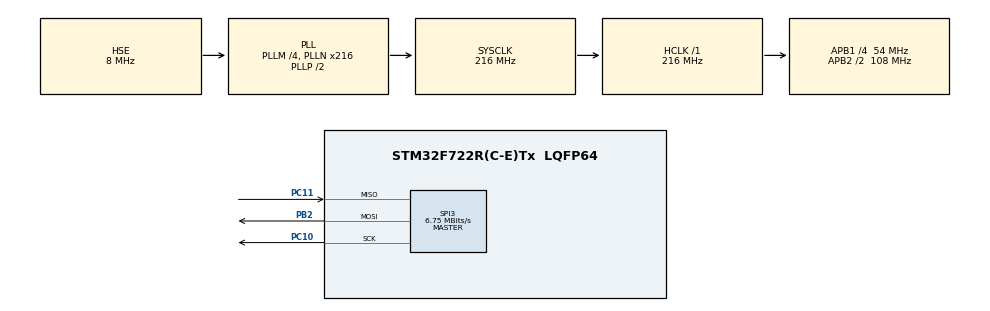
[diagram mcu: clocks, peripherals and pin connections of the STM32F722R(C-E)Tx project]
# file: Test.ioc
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CORTEX_M7.ART_ACCELERATOR_ENABLE=1
CORTEX_M7.CPU_DCache=Enabled
CORTEX_M7.CPU_ICache=Enabled
CORTEX_M7.PREFETCH_ENABLE=1
Mcu.Family=STM32F7
Mcu.Name=STM32F722R(C-E)Tx
Mcu.Package=LQFP64
NVIC.PriorityGroup=NVIC_PRIORITYGROUP_4
NVIC.SPI3_IRQn=true\:0\:0\:false\:false\:true\:true\:true\:true
PB2.Mode=Full_Duplex_Master
PB2.Signal=SPI3_MOSI
PC10.Mode=Full_Duplex_Master
PC10.Signal=SPI3_SCK
PC11.Mode=Full_Duplex_Master
PC11.Signal=SPI3_MISO
PH0-OSC_IN.Mode=HSE-External-Oscillator
PH0-OSC_IN.Signal=RCC_OSC_IN
PH1-OSC_OUT.Mode=HSE-External-Oscillator
PH1-OSC_OUT.Signal=RCC_OSC_OUT
ProjectManager.HeapSize=0x200
ProjectManager.StackSize=0x400
ProjectManager.TargetToolchain=STM32CubeIDE
RCC.AHBFreq_Value=216000000
RCC.APB1CLKDivider=RCC_HCLK_DIV4
RCC.APB1Freq_Value=54000000
RCC.APB1TimFreq_Value=108000000
RCC.APB2CLKDivider=RCC_HCLK_DIV2
RCC.APB2Freq_Value=108000000
RCC.APB2TimFreq_Value=216000000
RCC.CortexFreq_Value=216000000
RCC.HCLKFreq_Value=216000000
RCC.HSE_VALUE=8000000
RCC.HSI_VALUE=16000000
RCC.LSE_VALUE=32768
RCC.PLLM=4
RCC.PLLN=216
RCC.PLLSourceVirtual=RCC_PLLSOURCE_HSE
RCC.SYSCLKFreq_VALUE=216000000
RCC.SYSCLKSource=RCC_SYSCLKSOURCE_PLLCLK
RCC.USBFreq_Value=216000000
RCC.VCOOutputFreq_Value=432000000
SPI3.BaudRatePrescaler=SPI_BAUDRATEPRESCALER_8
SPI3.CalculateBaudRate=6.75 MBits/s
SPI3.DataSize=SPI_DATASIZE_8BIT
SPI3.Direction=SPI_DIRECTION_2LINES
SPI3.Mode=SPI_MODE_MASTER
SPI3.NSSPMode=SPI_NSS_PULSE_DISABLE
SPI3.VirtualType=VM_MASTER
board=custom

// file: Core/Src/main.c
/* USER CODE BEGIN Header */
/**
  ******************************************************************************
  * @file           : main.c
  * @brief          : Main program body
  ******************************************************************************
  * @attention
  *
  * Copyright (c) 2022 STMicroelectronics.
  * All rights reserved.
  *
  * This software is licensed under terms that can be found in the LICENSE file
  * in the root directory of this software component.
  * If no LICENSE file comes with this software, it is provided AS-IS.
  *
  ******************************************************************************
  */
/* USER CODE END Header */
#include "main.h"

SPI_HandleTypeDef hspi3;

void SystemClock_Config(void);
static void MX_GPIO_Init(void);
static void MX_SPI3_Init(void);

int main(void)
{

  /* Enable I-Cache---------------------------------------------------------*/
  SCB_EnableICache();

  /* Enable D-Cache---------------------------------------------------------*/
  SCB_EnableDCache();

  /* MCU Configuration--------------------------------------------------------*/

  /* Reset of all peripherals, Initializes the Flash interface and the Systick. */
  HAL_Init();

  /* Configure the system clock */
  SystemClock_Config();

  /* Initialize all configured peripherals */
  MX_GPIO_Init();
  MX_SPI3_Init();
  /* USER CODE BEGIN 2 */
  SystemCoreClockUpdate();
  /* USER CODE END 2 */

  /* Infinite loop */
  while (1)
  {

  }
}

void SystemClock_Config(void)
{
  RCC_OscInitTypeDef RCC_OscInitStruct = {0};
  RCC_ClkInitTypeDef RCC_ClkInitStruct = {0};

  /** Configure the main internal regulator output voltage
  */
  __HAL_RCC_PWR_CLK_ENABLE();
  __HAL_PWR_VOLTAGESCALING_CONFIG(PWR_REGULATOR_VOLTAGE_SCALE1);

  /** Initializes the RCC Oscillators according to the specified parameters
  * in the RCC_OscInitTypeDef structure.
  */
  RCC_OscInitStruct.OscillatorType = RCC_OSCILLATORTYPE_HSE;
  RCC_OscInitStruct.HSEState = RCC_HSE_ON;
  RCC_OscInitStruct.PLL.PLLState = RCC_PLL_ON;
  RCC_OscInitStruct.PLL.PLLSource = RCC_PLLSOURCE_HSE;
  RCC_OscInitStruct.PLL.PLLM = 4;
  RCC_OscInitStruct.PLL.PLLN = 216;
  RCC_OscInitStruct.PLL.PLLP = RCC_PLLP_DIV2;
  RCC_OscInitStruct.PLL.PLLQ = 2;
  if (HAL_RCC_OscConfig(&RCC_OscInitStruct) != HAL_OK)
  {
    Error_Handler();
  }

  /** Activate the Over-Drive mode
  */
  if (HAL_PWREx_EnableOverDrive() != HAL_OK)
  {
    Error_Handler();
  }

  /** Initializes the CPU, AHB and APB buses clocks
  */
  RCC_ClkInitStruct.ClockType = RCC_CLOCKTYPE_HCLK|RCC_CLOCKTYPE_SYSCLK
                              |RCC_CLOCKTYPE_PCLK1|RCC_CLOCKTYPE_PCLK2;
  RCC_ClkInitStruct.SYSCLKSource = RCC_SYSCLKSOURCE_PLLCLK;
  RCC_ClkInitStruct.AHBCLKDivider = RCC_SYSCLK_DIV1;
  RCC_ClkInitStruct.APB1CLKDivider = RCC_HCLK_DIV4;
  RCC_ClkInitStruct.APB2CLKDivider = RCC_HCLK_DIV2;

  if (HAL_RCC_ClockConfig(&RCC_ClkInitStruct, FLASH_LATENCY_7) != HAL_OK)
  {
    Error_Handler();
  }
}

static void MX_SPI3_Init(void)
{

  /* SPI3 parameter configuration*/
  hspi3.Instance = SPI3;
  hspi3.Init.Mode = SPI_MODE_MASTER;
  hspi3.Init.Direction = SPI_DIRECTION_2LINES;
  hspi3.Init.DataSize = SPI_DATASIZE_8BIT;
  hspi3.Init.CLKPolarity = SPI_POLARITY_LOW;
  hspi3.Init.CLKPhase = SPI_PHASE_1EDGE;
  hspi3.Init.NSS = SPI_NSS_SOFT;
  hspi3.Init.BaudRatePrescaler = SPI_BAUDRATEPRESCALER_8;
  hspi3.Init.FirstBit = SPI_FIRSTBIT_MSB;
  hspi3.Init.TIMode = SPI_TIMODE_DISABLE;
  hspi3.Init.CRCCalculation = SPI_CRCCALCULATION_DISABLE;
  hspi3.Init.CRCPolynomial = 7;
  hspi3.Init.CRCLength = SPI_CRC_LENGTH_DATASIZE;
  hspi3.Init.NSSPMode = SPI_NSS_PULSE_DISABLE;
  if (HAL_SPI_Init(&hspi3) != HAL_OK)
  {
    Error_Handler();
  }

}

static void MX_GPIO_Init(void)
{

  /* GPIO Ports Clock Enable */
  __HAL_RCC_GPIOH_CLK_ENABLE();
  __HAL_RCC_GPIOB_CLK_ENABLE();
  __HAL_RCC_GPIOC_CLK_ENABLE();

}

void Error_Handler(void)
{
  __disable_irq();
  while (1)
  {
  }
}
